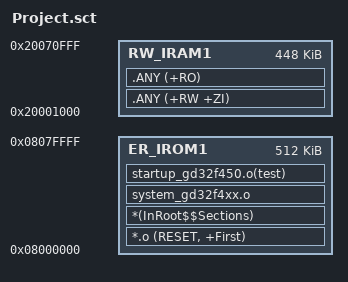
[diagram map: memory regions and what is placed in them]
; *************************************************************
; *** Scatter-Loading Description File generated by uVision ***
; *************************************************************

LR_IROM1 0x08000000 0x00080000  {    ; load region size_region
  ER_IROM1 0x08000000 0x00080000  {  ; load address = execution address
   *.o (RESET, +First)
   *(InRoot$$Sections)
   system_gd32f4xx.o
   startup_gd32f450.o(test)
  }
  RW_IRAM1 0x20001000 0x00070000  {  ; RW data
   .ANY (+RW +ZI)
	.ANY (+RO)
  }
}

